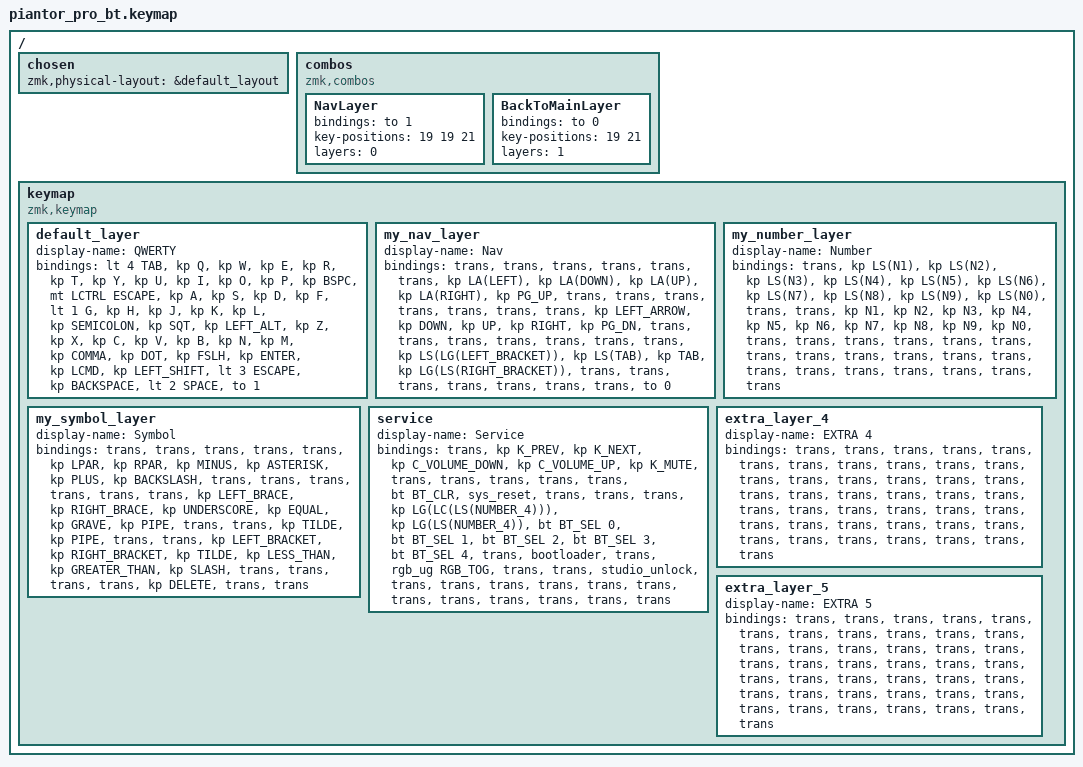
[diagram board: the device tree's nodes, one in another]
/*
 * Copyright (c) 2020 The ZMK Contributors
 *
 * SPDX-License-Identifier: MIT
 */

#include <behaviors.dtsi>
#include <dt-bindings/zmk/bt.h>
#include <dt-bindings/zmk/keys.h>
#include <dt-bindings/zmk/rgb.h>

/ {
    chosen { zmk,physical-layout = &default_layout; };
};

/ {
    combos {
        compatible = "zmk,combos";

        NavLayer {
            bindings = <&to 1>;
            key-positions = <19 19 21>;
            layers = <0>;
        };

        BackToMainLayer {
            bindings = <&to 0>;
            key-positions = <19 21>;
            layers = <1>;
        };
    };

    keymap {
        compatible = "zmk,keymap";

        default_layer {
            display-name = "QWERTY";

            // --------------------------------------------------------------------------------
            // |  TAB |  Q  |  W  |  E  |  R  |  T  |  Y  |  U   |  I  |  O  |  P  | BSPC |
            // | CTRL |  A  |  S  |  D  |  F  |  G  |  H  |  J   |  K  |  L  |  ;  |  '   |
            // | SHFT |  Z  |  X  |  C  |  V  |  B  |  N  |  M   |  ,  |  .  |  /  | ESC  |
            //                    | GUI | LWR | SPC | ENT | RSE  | ALT |

            bindings = <
&lt 4 TAB  &kp Q  &kp W  &kp E  &kp R  &kp T  &kp Y  &kp U  &kp I  &kp O  &kp P  &kp BSPC  &mt LCTRL ESCAPE  &kp A  &kp S  &kp D  &kp F  &lt 1 G  &kp H  &kp J  &kp K  &kp L  &kp SEMICOLON  &kp SQT  &kp LEFT_ALT  &kp Z  &kp X  &kp C  &kp V  &kp B  &kp N  &kp M  &kp COMMA  &kp DOT  &kp FSLH  &kp ENTER  &kp LCMD  &kp LEFT_SHIFT  &lt 3 ESCAPE  &kp BACKSPACE  &lt 2 SPACE  &to 1
            >;
        };

        my_nav_layer {
            display-name = "Nav";
            bindings = <
&trans  &trans  &trans  &trans  &trans  &trans  &kp LA(LEFT)  &kp LA(DOWN)  &kp LA(UP)  &kp LA(RIGHT)  &kp PG_UP  &trans  &trans  &trans  &trans  &trans  &trans  &trans  &kp LEFT_ARROW  &kp DOWN  &kp UP  &kp RIGHT  &kp PG_DN  &trans  &trans  &trans  &trans  &trans  &trans  &trans  &kp LS(LG(LEFT_BRACKET))  &kp LS(TAB)  &kp TAB  &kp LG(LS(RIGHT_BRACKET))  &trans  &trans  &trans  &trans  &trans  &trans  &trans  &to 0
            >;
        };

        my_number_layer {
            display-name = "Number";
            bindings = <
&trans  &kp LS(N1)  &kp LS(N2)  &kp LS(N3)  &kp LS(N4)  &kp LS(N5)  &kp LS(N6)  &kp LS(N7)  &kp LS(N8)  &kp LS(N9)  &kp LS(N0)  &trans  &trans  &kp N1  &kp N2  &kp N3  &kp N4  &kp N5  &kp N6  &kp N7  &kp N8  &kp N9  &kp N0  &trans  &trans  &trans  &trans  &trans  &trans  &trans  &trans  &trans  &trans  &trans  &trans  &trans  &trans  &trans  &trans  &trans  &trans  &trans
            >;
        };

        my_symbol_layer {
            display-name = "Symbol";
            bindings = <
&trans  &trans  &trans  &trans  &trans  &kp LPAR  &kp RPAR  &kp MINUS  &kp ASTERISK  &kp PLUS  &kp BACKSLASH  &trans  &trans  &trans  &trans  &trans  &trans  &kp LEFT_BRACE  &kp RIGHT_BRACE  &kp UNDERSCORE  &kp EQUAL  &kp GRAVE  &kp PIPE  &trans  &trans  &kp TILDE  &kp PIPE  &trans  &trans  &kp LEFT_BRACKET  &kp RIGHT_BRACKET  &kp TILDE  &kp LESS_THAN  &kp GREATER_THAN  &kp SLASH  &trans  &trans  &trans  &trans  &kp DELETE  &trans  &trans
            >;
        };

        service {
            display-name = "Service";

            // -----------------------------------------------------------------------------------------
            // |  TAB |  1  |  2  |  3  |  4  |  5    |  6  |  7  |  8  |  9  |  0  | BSPC |
            // | CTRL | BT1 | BT2 | BT3 | BT4 | BT5   | LFT | DWN |  UP | RGT |     |      |
            // | SHFT | BTCR| RGB | RST | BOOT| Unlock|     |     |     |     |     |      |
            //                    | GUI |     | SPC   | ENT |     | ALT |

            bindings = <
&trans  &kp K_PREV  &kp K_NEXT  &kp C_VOLUME_DOWN  &kp C_VOLUME_UP  &kp K_MUTE  &trans  &trans  &trans  &trans  &trans  &bt BT_CLR  &sys_reset  &trans  &trans  &trans  &kp LG(LC(LS(NUMBER_4)))  &kp LG(LS(NUMBER_4))  &bt BT_SEL 0  &bt BT_SEL 1  &bt BT_SEL 2  &bt BT_SEL 3  &bt BT_SEL 4  &trans  &bootloader  &trans  &rgb_ug RGB_TOG  &trans  &trans  &studio_unlock  &trans  &trans  &trans  &trans  &trans  &trans  &trans  &trans  &trans  &trans  &trans  &trans
            >;
        };

        extra_layer_4 {
            display-name = "EXTRA 4";
            bindings = <
&trans  &trans  &trans  &trans  &trans  &trans  &trans  &trans  &trans  &trans  &trans  &trans  &trans  &trans  &trans  &trans  &trans  &trans  &trans  &trans  &trans  &trans  &trans  &trans  &trans  &trans  &trans  &trans  &trans  &trans  &trans  &trans  &trans  &trans  &trans  &trans  &trans  &trans  &trans  &trans  &trans  &trans
            >;
        };

        extra_layer_5 {
            display-name = "EXTRA 5";
            bindings = <
&trans  &trans  &trans  &trans  &trans  &trans  &trans  &trans  &trans  &trans  &trans  &trans  &trans  &trans  &trans  &trans  &trans  &trans  &trans  &trans  &trans  &trans  &trans  &trans  &trans  &trans  &trans  &trans  &trans  &trans  &trans  &trans  &trans  &trans  &trans  &trans  &trans  &trans  &trans  &trans  &trans  &trans
            >;
        };
    };
};
